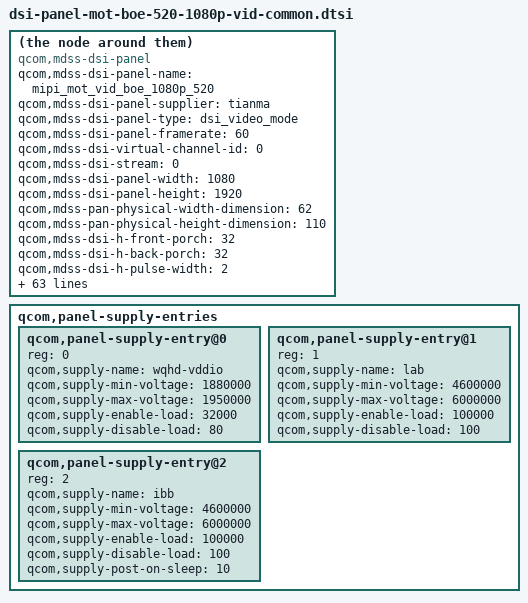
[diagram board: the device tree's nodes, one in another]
/* Copyright (c) 2016, The Linux Foundation. All rights reserved.
 *
 * This program is free software; you can redistribute it and/or modify
 * it under the terms of the GNU General Public License version 2 and
 * only version 2 as published by the Free Software Foundation.
 *
 * This program is distributed in the hope that it will be useful,
 * but WITHOUT ANY WARRANTY; without even the implied warranty of
 * MERCHANTABILITY or FITNESS FOR A PARTICULAR PURPOSE.  See the
 * GNU General Public License for more details.
 */

compatible = "qcom,mdss-dsi-panel";
qcom,mdss-dsi-panel-name = "mipi_mot_vid_boe_1080p_520";
qcom,mdss-dsi-panel-supplier = "tianma";
qcom,mdss-dsi-panel-type = "dsi_video_mode";
qcom,mdss-dsi-panel-framerate = <60>;
qcom,mdss-dsi-virtual-channel-id = <0>;
qcom,mdss-dsi-stream = <0>;
qcom,mdss-dsi-panel-width = <1080>;
qcom,mdss-dsi-panel-height = <1920>;
qcom,mdss-pan-physical-width-dimension = <62>;
qcom,mdss-pan-physical-height-dimension = <110>;
qcom,mdss-dsi-h-front-porch = <32>;
qcom,mdss-dsi-h-back-porch = <32>;
qcom,mdss-dsi-h-pulse-width = <2>;
qcom,mdss-dsi-h-sync-skew = <0>;
qcom,mdss-dsi-v-back-porch = <16>;
qcom,mdss-dsi-v-front-porch = <16>;
qcom,mdss-dsi-v-pulse-width = <2>;
qcom,mdss-dsi-h-left-border = <0>;
qcom,mdss-dsi-h-right-border = <0>;
qcom,mdss-dsi-v-top-border = <0>;
qcom,mdss-dsi-v-bottom-border = <0>;
qcom,mdss-dsi-bpp = <24>;
qcom,mdss-dsi-underflow-color = <0xff>;
qcom,mdss-dsi-border-color = <0>;
qcom,mdss-dsi-on-command = [
	39 01 00 00 00 00 02 51 CC
	39 01 00 00 00 00 02 53 2C
	39 01 00 00 00 00 02 55 01
	05 01 00 00 82 00 02 11 00
	29 01 00 00 00 00 02 B0 00
	29 01 00 00 00 00 02 D6 01
	29 01 00 00 00 00 2e C1 80 08 01 FF AB 2B A3 39 4F 29 C5 9A 53 EA 7F A5
		5C 63 4A 29 70 8C 18 57 FD 0F 00 00 00 00 00 00 00 00 40 00 22
		03 02 03 82 00 01 00 01
	29 01 00 00 00 00 12 CB FC FF F9 FF 03 04 8E 19 07 02 F8 01 00 F8 01 00
		40
	05 01 00 00 0A 00 02 29 00];	/* display on */

qcom,mdss-dsi-off-command = [
	05 01 00 00 23 00 01 28		/* display_off */
	05 01 00 00 78 00 01 10];	/* enter sleep mode */


qcom,mdss-dsi-on-command-state = "dsi_lp_mode";
qcom,mdss-dsi-off-command-state = "dsi_lp_mode";

qcom,mdss-dsi-cabc-ui-command = [15 01 00 00 00 00 02 55 01];
qcom,mdss-dsi-cabc-ui-command-state = "dsi_hs_mode";
qcom,mdss-dsi-cabc-mv-command = [15 01 00 00 00 00 02 55 03];
qcom,mdss-dsi-cabc-mv-command-state = "dsi_hs_mode";
qcom,mdss-dsi-cabc-dis-command = [15 01 00 00 00 00 02 55 00];
qcom,mdss-dsi-cabc-dis-command-state = "dsi_hs_mode";
qcom,mdss-dsi-hbm-on-command = [15 01 00 00 00 00 02 51 FF];
qcom,mdss-dsi-hbm-on-command-state = "dsi_hs_mode";
qcom,mdss-dsi-hbm-off-command = [15 01 00 00 00 00 02 51 CC];
qcom,mdss-dsi-hbm-off-command-state = "dsi_hs_mode";
qcom,mdss-dsi-hbm-type = "lcd-dcs-wled";

qcom,mdss-dsi-h-sync-pulse = <0>;
qcom,mdss-dsi-traffic-mode = "burst_mode";
qcom,mdss-dsi-bllp-eof-power-mode;
qcom,mdss-dsi-bllp-power-mode;
qcom,mdss-dsi-lane-0-state;
qcom,mdss-dsi-lane-1-state;
qcom,mdss-dsi-lane-2-state;
qcom,mdss-dsi-lane-3-state;
qcom,mdss-dsi-panel-timings = [00 19 05 06 0A 0F 05 06 05 03 04 00];
qcom,mdss-dsi-panel-timings-phy-v2 = [23 1e 07 08 05 03 04 a0
	23 1e 07 08 05 03 04 a0
	23 1e 07 08 05 03 04 a0
	23 1e 07 08 05 03 04 a0
	23 18 07 08 05 03 04 a0];
qcom,mdss-dsi-t-clk-post = <0x0d>;
qcom,mdss-dsi-t-clk-pre = <0x2d>;
qcom,mdss-dsi-bl-min-level = <1>;
qcom,mdss-dsi-bl-max-level = <4095>;
qcom,mdss-dsi-dma-trigger = "trigger_sw";
qcom,mdss-dsi-mdp-trigger = "none";
qcom,mdss-dsi-bl-pmic-control-type = "bl_ctrl_wled";
qcom,mdss-dsi-reset-sequence = <1 20>;
qcom,mdss-dsi-lp11-init;
qcom,mdss-dsi-tx-eot-append;
qcom,mdss-dsi-init-delay-us = <50000>;
qcom,mdss-dsi-panel-on-check-value = <0x0c>;

qcom,panel-supply-entries {
	#address-cells = <1>;
	#size-cells = <0>;

	qcom,panel-supply-entry@0 {
		reg = <0>;
		qcom,supply-name = "wqhd-vddio";
		qcom,supply-min-voltage = <1880000>;
		qcom,supply-max-voltage = <1950000>;
		qcom,supply-enable-load = <32000>;
		qcom,supply-disable-load = <80>;
	};

	qcom,panel-supply-entry@1 {
		reg = <1>;
		qcom,supply-name = "lab";
		qcom,supply-min-voltage = <4600000>;
		qcom,supply-max-voltage = <6000000>;
		qcom,supply-enable-load = <100000>;
		qcom,supply-disable-load = <100>;
	};

	qcom,panel-supply-entry@2 {
		reg = <2>;
		qcom,supply-name = "ibb";
		qcom,supply-min-voltage = <4600000>;
		qcom,supply-max-voltage = <6000000>;
		qcom,supply-enable-load = <100000>;
		qcom,supply-disable-load = <100>;
		qcom,supply-post-on-sleep = <10>;
	};
};
